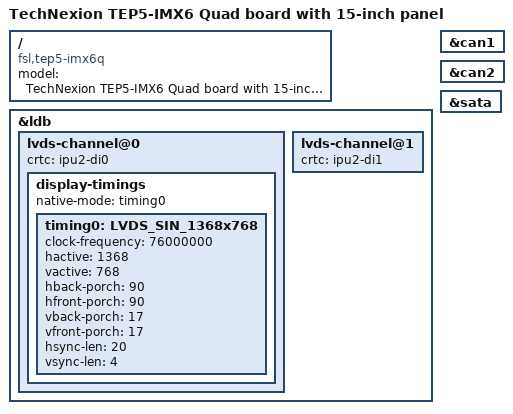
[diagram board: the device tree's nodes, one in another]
/*
 * Copyright 2018 TechNexion Ltd.
 *
 * Author: Ray Chang <ray.chang@technexion.com>
 *
 * The code contained herein is licensed under the GNU General Public
 * License. You may obtain a copy of the GNU General Public License
 * Version 2 or later at the following locations:
 *
 * http://www.opensource.org/licenses/gpl-license.html
 * http://www.gnu.org/copyleft/gpl.html
 */

/dts-v1/;

#include <dt-bindings/interrupt-controller/irq.h>
#include "imx6q.dtsi"
#include "imx6qdl-tep5.dtsi"

/ {
	model = "TechNexion TEP5-IMX6 Quad board with 15-inch panel";
	compatible = "fsl,tep5-imx6q", "fsl,imx6q";
};

&ldb {
	lvds-channel@0 {
		crtc = "ipu2-di0";

		/delete-node/ display-timings;

		display-timings {
			native-mode = <&timing0>;
			timing0: LVDS_SIN_1368x768 {
				clock-frequency = <76000000>;
				hactive = <1368>;
				vactive = <768>;
				hback-porch = <90>;
				hfront-porch = <90>;
				vback-porch = <17>;
				vfront-porch = <17>;
				hsync-len = <20>;
				vsync-len = <4>;
			};
		};
	};

	lvds-channel@1 {
		crtc = "ipu2-di1";
	};
};

&can1{
	status = "okay";
};

&can2{
	status = "okay";
};

#if 0
&mxcfb3 {
	status = "okay";
};

&mxcfb4 {
	status = "okay";
};
#endif

&sata {
	status = "okay";
};
